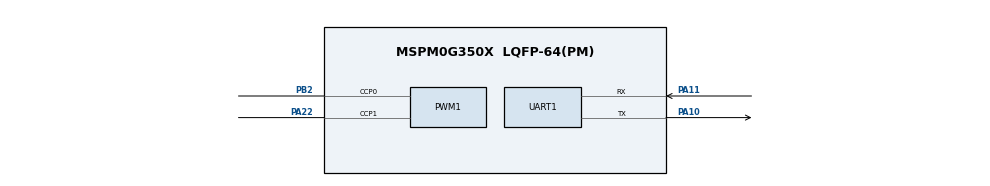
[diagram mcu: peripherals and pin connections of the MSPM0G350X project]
/**
 * @cliArgs --device "MSPM0G350X" --part "Default" --package "LQFP-64(PM)" --product "mspm0_sdk@2.04.00.06"
 * @versions {"tool":"1.22.0+3893"}
 */

/**
 * Import the modules used in this configuration.
 */
const GPIO    = scripting.addModule("/ti/driverlib/GPIO", {}, false);
const GPIO1   = GPIO.addInstance();
const GPIO2   = GPIO.addInstance();
const GPIO3   = GPIO.addInstance();
const GPIO4   = GPIO.addInstance();
const GPIO5   = GPIO.addInstance();
const PWM     = scripting.addModule("/ti/driverlib/PWM", {}, false);
const PWM1    = PWM.addInstance();
const SYSCTL  = scripting.addModule("/ti/driverlib/SYSCTL");
const SYSTICK = scripting.addModule("/ti/driverlib/SYSTICK");
const TIMER   = scripting.addModule("/ti/driverlib/TIMER", {}, false);
const TIMER1  = TIMER.addInstance();
const UART    = scripting.addModule("/ti/driverlib/UART", {}, false);
const UART1   = UART.addInstance();

/**
 * Write custom configuration values to the imported modules.
 */
GPIO1.$name                              = "GPIO_LED";
GPIO1.associatedPins[0].internalResistor = "PULL_DOWN";
GPIO1.associatedPins[0].$name            = "PIN_LED_1";
GPIO1.associatedPins[0].assignedPort     = "PORTB";
GPIO1.associatedPins[0].assignedPin      = "22";

const Board = scripting.addModule("/ti/driverlib/Board", {}, false);

GPIO2.$name                              = "GPIO_KEY";
GPIO2.associatedPins[0].direction        = "INPUT";
GPIO2.associatedPins[0].assignedPort     = "PORTB";
GPIO2.associatedPins[0].$name            = "PIN_KEY_S1";
GPIO2.associatedPins[0].internalResistor = "PULL_UP";
GPIO2.associatedPins[0].assignedPin      = "21";

GPIO3.$name                          = "GPIO_OLED";
GPIO3.associatedPins.create(2);
GPIO3.associatedPins[0].$name        = "PIN_SCL";
GPIO3.associatedPins[0].assignedPort = "PORTA";
GPIO3.associatedPins[0].assignedPin  = "13";
GPIO3.associatedPins[1].$name        = "PIN_SDA";
GPIO3.associatedPins[1].assignedPort = "PORTA";
GPIO3.associatedPins[1].assignedPin  = "12";

GPIO4.port                          = "PORTB";
GPIO4.$name                         = "GPIO_Encoder";
GPIO4.associatedPins.create(2);
GPIO4.associatedPins[0].direction   = "INPUT";
GPIO4.associatedPins[0].interruptEn = true;
GPIO4.associatedPins[0].polarity    = "RISE_FALL";
GPIO4.associatedPins[0].$name       = "PIN_A";
GPIO4.associatedPins[0].assignedPin = "16";
GPIO4.associatedPins[1].direction   = "INPUT";
GPIO4.associatedPins[1].$name       = "PIN_B";
GPIO4.associatedPins[1].assignedPin = "17";
GPIO4.associatedPins[1].polarity    = "RISE_FALL";

GPIO5.$name                          = "GPIO_HSR04";
GPIO5.associatedPins.create(2);
GPIO5.associatedPins[0].$name        = "PIN_Trig";
GPIO5.associatedPins[0].assignedPort = "PORTB";
GPIO5.associatedPins[0].assignedPin  = "24";
GPIO5.associatedPins[1].$name        = "PIN_Echo";
GPIO5.associatedPins[1].direction    = "INPUT";
GPIO5.associatedPins[1].assignedPort = "PORTB";
GPIO5.associatedPins[1].assignedPin  = "25";
GPIO5.associatedPins[1].interruptEn  = true;
GPIO5.associatedPins[1].polarity     = "RISE_FALL";

PWM1.$name                      = "PWM_0";
PWM1.clockDivider               = 8;
PWM1.timerStartTimer            = true;
PWM1.peripheral.$assign         = "TIMG6";
PWM1.peripheral.ccp0Pin.$assign = "PB2";
PWM1.peripheral.ccp1Pin.$assign = "PA22";
PWM1.PWM_CHANNEL_0.$name        = "ti_driverlib_pwm_PWMTimerCC0";
PWM1.PWM_CHANNEL_1.$name        = "ti_driverlib_pwm_PWMTimerCC1";
PWM1.ccp0PinConfig.$name        = "ti_driverlib_gpio_GPIOPinGeneric0";
PWM1.ccp1PinConfig.$name        = "ti_driverlib_gpio_GPIOPinGeneric1";

SYSCTL.forceDefaultClkConfig = true;
SYSCTL.clockTreeEn           = true;

SYSTICK.periodEnable      = true;
SYSTICK.period            = 32;
SYSTICK.interruptEnable   = true;
SYSTICK.interruptPriority = "0";
SYSTICK.systickEnable     = true;

TIMER1.$name              = "TIMER_0";
TIMER1.timerClkPrescale   = 256;
TIMER1.timerMode          = "PERIODIC";
TIMER1.timerPeriod        = "500 ms";
TIMER1.interrupts         = ["ZERO"];
TIMER1.peripheral.$assign = "TIMG0";

UART1.$name                    = "UART_0";
UART1.targetBaudRate           = 115200;
UART1.enabledInterrupts        = ["RX"];
UART1.peripheral.rxPin.$assign = "PA11";
UART1.peripheral.txPin.$assign = "PA10";
UART1.txPinConfig.$name        = "ti_driverlib_gpio_GPIOPinGeneric2";
UART1.rxPinConfig.$name        = "ti_driverlib_gpio_GPIOPinGeneric3";

/**
 * Pinmux solution for unlocked pins/peripherals. This ensures that minor changes to the automatic solver in a future
 * version of the tool will not impact the pinmux you originally saw.  These lines can be completely deleted in order to
 * re-solve from scratch.
 */
GPIO1.associatedPins[0].pin.$suggestSolution = "PB22";
Board.peripheral.$suggestSolution            = "DEBUGSS";
Board.peripheral.swclkPin.$suggestSolution   = "PA20";
Board.peripheral.swdioPin.$suggestSolution   = "PA19";
GPIO2.associatedPins[0].pin.$suggestSolution = "PB21";
GPIO3.associatedPins[0].pin.$suggestSolution = "PA13";
GPIO3.associatedPins[1].pin.$suggestSolution = "PA12";
GPIO4.associatedPins[0].pin.$suggestSolution = "PB16";
GPIO4.associatedPins[1].pin.$suggestSolution = "PB17";
GPIO5.associatedPins[0].pin.$suggestSolution = "PB24";
GPIO5.associatedPins[1].pin.$suggestSolution = "PB25";
UART1.peripheral.$suggestSolution            = "UART0";
